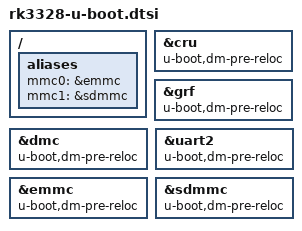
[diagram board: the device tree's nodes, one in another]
/*
 * (C) Copyright 2018 Rockchip Electronics Co., Ltd
 *
 * SPDX-License-Identifier:     GPL-2.0+
 */

/ {
	aliases {
		mmc0 = &emmc;
		mmc1 = &sdmmc;
	};
};

&cru {
	u-boot,dm-pre-reloc;
};

&grf {
	u-boot,dm-pre-reloc;
};

&dmc {
	u-boot,dm-pre-reloc;
};

&uart2 {
	u-boot,dm-pre-reloc;
};

&emmc {
	u-boot,dm-pre-reloc;
};

&sdmmc {
	u-boot,dm-pre-reloc;
};
